# UART0_UART0 register map
Vendor: Texas Instruments
Peripheral module from a debugger description file (folder AM263).
Registers are 32-bit, access per field, reset 0x0 unless marked. A register's access mark holds for its fields unless they carry their own. Offsets are as the file gives them; lines under a group give offsets from that group; [hi:lo] are bit positions; {n}, {i} and the like mark numbered series; 'fields as' and 'values as' point back to an identical list; <NAME> marks a mode.

## UART0_UART0
0x00 UART0_DLL 8-bit rw
  [7:0] CLOCK_LSB — Used to store the 8-bit LSB divisor value
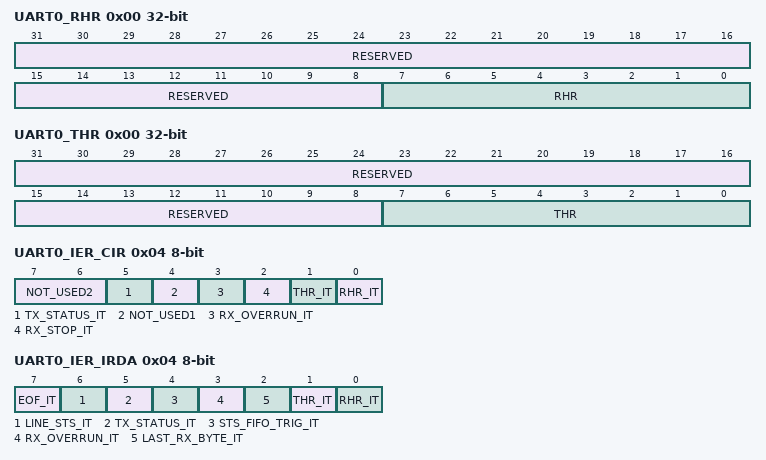
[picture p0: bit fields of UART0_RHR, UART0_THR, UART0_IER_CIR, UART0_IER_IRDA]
0x00 UART0_RHR ro
  [31:8] RESERVED — Not Defined
  [7:0] RHR — Receive holding register
0x00 UART0_THR
  [31:8] RESERVED ro — Not Defined
  [7:0] THR wo — TRANSMIT HOLDING REGISTER
0x04 UART0_DLH 8-bit rw
  [7:0] CLOCK_MSB — Used to store the 8-bit MSB divisor value
0x04 UART0_IER_CIR 8-bit rw
  [7:6] NOT_USED2 — Not Defined
  [5] TX_STATUS_IT — Not Defined 0 | TX_STATUS_IT_VALUE_0Disables the TX status interrupt. 1 | TX_STATUS_IT_VALUE_1Enables the TX status interrupt.
  [4] NOT_USED1 — Not Defined
  [3] RX_OVERRUN_IT — Not Defined 0 | RX_OVERRUN_IT_VALUE_0Disables the RX overrun interrupt. 1 | RX_OVERRUN_IT_VALUE_1Enables the RX overrun interrupt.
  [2] RX_STOP_IT — Not Defined 0 | RX_STOP_IT_VALUE_0Disables the receive stop interrupt. 1 | RX_STOP_IT_VALUE_1Enables the receive stop interrupt.
  [1] THR_IT — Not Defined 0 | THR_IT_VALUE_0Disables the THR interrupt. 1 | THR_IT_VALUE_1Enables the THR interrupt.
  [0] RHR_IT — Not Defined 0 | RHR_IT_VALUE_0Disables the RHR interrupt. 1 | RHR_IT_VALUE_1Enables the RHR interrupt.
0x04 UART0_IER_IRDA 8-bit rw
  [7] EOF_IT — Not Defined 0 | EOF_IT_VALUE_0Disables the received EOF interrupt. 1 | EOF_IT_VALUE_1Enables the received EOF interrupt.
  [6] LINE_STS_IT — Not Defined 0 | LINE_STS_IT_VALUE_0Disables the receiver line status interrupt. 1 | LINE_STS_IT_VALUE_1Enables the receiver line status interrupt.
  [5] TX_STATUS_IT — Not Defined 0 | TX_STATUS_IT_VALUE_0Disables the TX status interrupt. 1 | TX_STATUS_IT_VALUE_1Enables the TX status interrupt.
  [4] STS_FIFO_TRIG_IT — Not Defined 0 | STS_FIFO_TRIG_IT_VALUE_0Disables the status FIFO trigger level interrupt. 1 | STS_FIFO_TRIG_IT_VALUE_1Enables the status FIFO trigger level interrupt.
  [3] RX_OVERRUN_IT — Not Defined 0 | RX_OVERRUN_IT_VALUE_0Disables the RX overrun interrupt. 1 | RX_OVERRUN_IT_VALUE_1Enables the RX overrun interrupt.
  [2] LAST_RX_BYTE_IT — Not Defined 0 | LAST_RX_BYTE_IT_VALUE_0Disables the last byte of frame in RX FIFO interrupt. 1 | LAST_RX_BYTE_IT_VALUE_1Enables the last byte of frame in RX FIFO interrupt.
  [1] THR_IT — Not Defined 0 | THR_IT_VALUE_0Disables the THR interrupt. 1 | THR_IT_VALUE_1Enables the THR interrupt.
  [0] RHR_IT — Not Defined 0 | RHR_IT_VALUE_0Disables the RHR interrupt. 1 | RHR_IT_VALUE_1Enables the RHR interrupt.
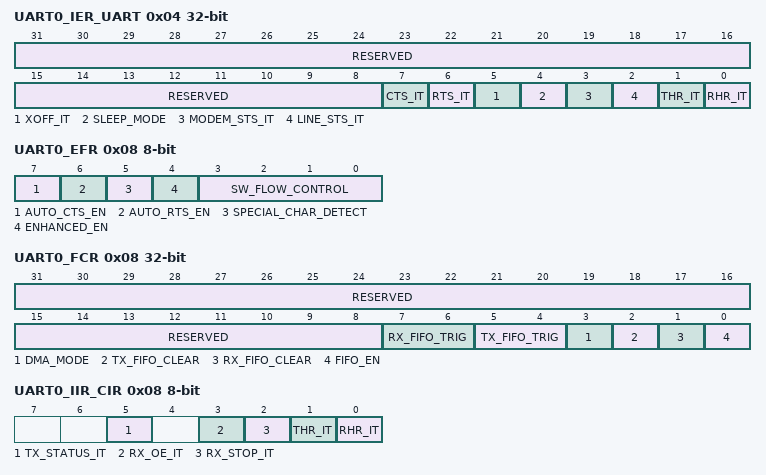
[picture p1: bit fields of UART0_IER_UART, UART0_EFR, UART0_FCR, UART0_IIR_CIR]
0x04 UART0_IER_UART
  [31:8] RESERVED ro — Not Defined
  [7] CTS_IT rw — Not Defined 0 | CTS_IT_VALUE_0Disables the CTS* interrupt 1 | CTS_IT_VALUE_1Enables the CTS* interrupt
  [6] RTS_IT rw — Not Defined 0 | RTS_IT_VALUE_0Disables the RTS* interrupt 1 | RTS_IT_VALUE_1Enables the RTS* interrupt
  [5] XOFF_IT rw — Not Defined 0 | XOFF_IT_VALUE_0Disables the XOFF interrupt 1 | XOFF_IT_VALUE_1Enables the XOFF interrupt
  [4] SLEEP_MODE rw — Not Defined 0 | SLEEP_MODE_VALUE_0Disables sleep mode 1 | SLEEP_MODE_VALUE_1Enables sleep mode (stop baud rate clock when the module is inactive)
  [3] MODEM_STS_IT rw — Not Defined 0 | MODEM_STS_IT_VALUE_0Disables the modem status register interrupt 1 | MODEM_STS_IT_VALUE_1Enables the modem status register interrupt
  [2] LINE_STS_IT rw — Not Defined 0 | LINE_STS_IT_U_VALUE_0Disables the receiver line status interrupt 1 | LINE_STS_IT_U_VALUE_1Enables the receiver line status interrupt
  [1] THR_IT rw — Not Defined 0 | THR_IT_VALUE_0Disables the THR interrupt 1 | THR_IT_VALUE_1Enables the THR interrupt
  [0] RHR_IT rw — Not Defined 0 | RHR_IT_VALUE_0Disables the RHR interrupt and time out interrupt. 1 | RHR_IT_VALUE_1Enables the RHR interrupt and time out interrupt.
0x08 UART0_EFR 8-bit rw
  [7] AUTO_CTS_EN — Auto-CTS enable bit. 0: Normal operation. 1: Auto-CTS flow control is enabled i.e. transmission is halted when the CTS* pin is high (inactive).
  [6] AUTO_RTS_EN — Auto-RTS enable bit. 0: Normal operation. 1: Auto- RTS flow control is enabled i.e. RTS* pin goes high (inactive) when the receiver FIFO HALT trigger level, TCR[3:0], is reached, and goes low (active) when the receiver FIFO RESTORE transmission trigger level is reached.
  [5] SPECIAL_CHAR_DETECT — 0: Normal operation. 1: Special character detect enable. Received data is compared with XOFF2 data. If a match occurs the received data is transferred to RX FIFO and IIR bit 4 is set to 1 to indicate a special character has been detected.
  [4] ENHANCED_EN — Enhanced functions write enable bit. 0: Disables writing to IER bits 4-7, FCR bits 4-5, and MCR bits 5-7. 1: Enables writing to IER bits 4-7, FCR bits 4-5, and MCR bits 5-7.
  [3:0] SW_FLOW_CONTROL — Combinations of Software flow control can be selected by programming bit 3 - bit 0. See Software Flow Control Options
0x08 UART0_FCR
  [31:8] RESERVED ro — Not Defined
  [7:6] RX_FIFO_TRIG wo — Sets the trigger level for the RX FIFO:If SCR[7] = 0 and TLR[7:4] = 0000:00: 8 characters01: 16 characters10: 56 characters11: 60 charactersIf SCR[7] = 0 and TLR[7:4] != 0000, RX_FIFO_TRIG is not considered.If SCR[7]=1, RX_FIFO_TRIG is 2 LSB of the trigger level [1-63 on 6 bits] with the granularity 1.
  [5:4] TX_FIFO_TRIG wo — Sets the trigger level for the TX FIFO:If SCR[6] = 0 and TLR[3:0] = 0000:00: 8 spaces01: 16 spaces10: 32 spaces11: 56 spacesIf SCR[6] = 0 and TLR[3:0] != 0000, TX_FIFO_TRIG is not considered.If SCR[6]=1, TX_FIFO_TRIG is 2 LSB of the trigger level [1-63 on 6 bits] with the granularity 1
  [3] DMA_MODE wo — This register is considered if SCR[0] = 0. Write0 | DMA_MODE_VALUE_0DMA_MODE 0 (No DMA) Write1 | DMA_MODE_VALUE_1DMA_MODE 1 (UART_nDMA_REQ[0] in TX, UART_nDMA_REQ[1] in RX)
  [2] TX_FIFO_CLEAR wo — Not Defined Write0 | TX_FIFO_CLEAR_VALUE_0No change Write1 | TX_FIFO_CLEAR_VALUE_1Clears the transmit FIFO and resets its counter logic to zero. Returns to zero after clearing FIFO.
  [1] RX_FIFO_CLEAR wo — Not Defined Write0 | RX_FIFO_CLEAR_VALUE_0No change Write1 | RX_FIFO_CLEAR_VALUE_1Clears the receive FIFO and resets its counter logic to zero. Returns to zero after clearing FIFO.
  [0] FIFO_EN wo — Not Defined Write0 | FIFO_EN_VALUE_0Disables the transmit and receive FIFOs. The transmit and receive holding registers are one byte FIFOs. Write1 | FIFO_EN_VALUE_1: Enables the transmit and receive FIFOs.The transmit and receive holding registers are 64-bytes FIFOs.
0x08 UART0_IIR_CIR 8-bit ro
  [5] TX_STATUS_IT — Not Defined Read0 | TX_STATUS_IT_VALUE_0TX status interrupt inactive Read1 | TX_STATUS_IT_VALUE_1TX status interrupt active
  [3] RX_OE_IT — Not Defined Read0 | RX_OE_IT_VALUE_0RX overrun interrupt inactive Read1 | RX_OE_IT_VALUE_1RX overrun interrupt active
  [2] RX_STOP_IT — Not Defined Read0 | RX_STOP_IT_VALUE_0Receive stop interrupt inactive Read1 | RX_STOP_IT_VALUE_1Receive stop interrupt active
  [1] THR_IT — Not Defined Read0 | THR_IT_VALUE_0THR interrupt inactive Read1 | THR_IT_VALUE_1THR interrupt active
  [0] RHR_IT — Not Defined Read0 | RHR_IT_VALUE_0RHR interrupt inactive Read1 | RHR_IT_VALUE_1RHR interrupt active
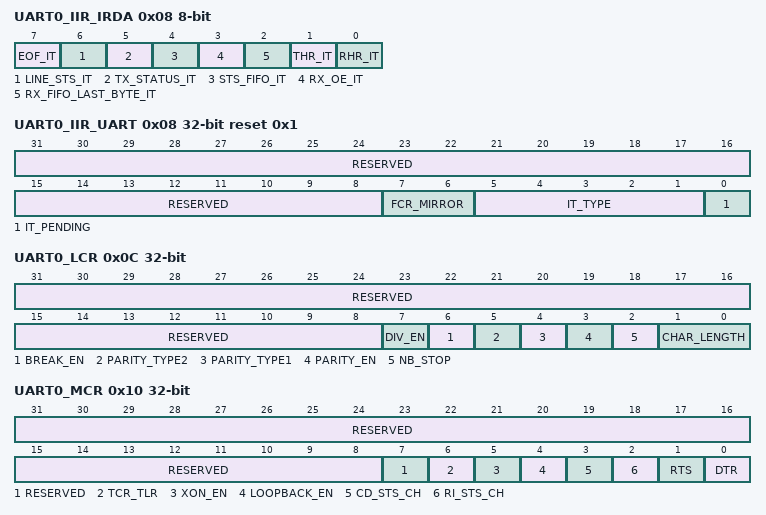
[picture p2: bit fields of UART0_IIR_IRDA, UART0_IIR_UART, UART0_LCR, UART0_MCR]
0x08 UART0_IIR_IRDA 8-bit ro
  [7] EOF_IT — Not Defined Read0 | EOF_IT_VALUE_0Received EOF interrupt inactive Read1 | EOF_IT_VALUE_1Received EOF interrupt active
  [6] LINE_STS_IT — Not Defined Read0 | LINE_STS_IT_VALUE_0Receiver line status interrupt inactive Read1 | LINE_STS_IT_VALUE_1Receiver line status interrupt active
  [5] TX_STATUS_IT — Not Defined Read0 | TX_STATUS_IT_VALUE_0TX status interrupt inactive Read1 | TX_STATUS_IT_VALUE_1TX status interrupt active
  [4] STS_FIFO_IT — Not Defined Read0 | STS_FIFO_IT_VALUE_0Status FIFO trigger level interrupt inactive Read1 | STS_FIFO_IT_VALUE_1Status FIFO trigger level interrupt active
  [3] RX_OE_IT — Not Defined Read0 | RX_OE_IT_VALUE_0RX overrun interrupt inactive Read1 | RX_OE_IT_VALUE_1RX overrun interrupt active
  [2] RX_FIFO_LAST_BYTE_IT — Not Defined Read0 | RX_FIFO_LAST_BYTE_IT_VALUE_0Last byte of frame in RX FIFO interrupt inactive Read1 | RX_FIFO_LAST_BYTE_IT_VALUE_1Last byte of frame in RX FIFO interrupt active
  [1] THR_IT — Not Defined Read0 | THR_IT_VALUE_0THR interrupt inactive Read1 | THR_IT_VALUE_1THR interrupt active
  [0] RHR_IT — Not Defined Read0 | RHR_IT_VALUE_0RHR interrupt inactive Read1 | RHR_IT_VALUE_1RHR interrupt active
0x08 UART0_IIR_UART ro reset 0x1
  [31:8] RESERVED — Not Defined
  [7:6] FCR_MIRROR — Mirror the contents of FCR[0] on both bits.
  [5:1] IT_TYPE — Not Defined Read0x00 | IT_TYPE_VALUE_0Modem Interrupt. Priority=4 Read0x01 | IT_TYPE_VALUE_1THR interrupt. Priority=3 Read0x02 | IT_TYPE_VALUE_2RHR interrupt. Priority=2 Read0x03 | IT_TYPE_VALUE_3Receiver line status error. Priority=3 Read0x06 | IT_TYPE_VALUE_6Rx timeout. Priority=2 Read0x08 | IT_TYPE_VALUE_8Xoff/Special character. Priority=5 Read0x10 | IT_TYPE_VALUE_10CTS, RTS, DSR change state from active (low) to inactive (high). Priority=6
  [0] IT_PENDING — Not Defined Read0 | IT_PENDING_VALUE_0An interrupt is pending Read1 | IT_PENDING_VALUE_1No interrupt is pending
0x0C UART0_LCR
  [31:8] RESERVED ro — Not Defined
  [7] DIV_EN rw — Not Defined 0 | DIV_EN_VALUE_0Normal operating condition 1 | DIV_EN_VALUE_1Divisor latch enable. Allows to access to DLL, DLH and other registers (refer to the registers mapping)
  [6] BREAK_EN rw — Break control bit. 0 | BREAK_EN_VALUE_0Normal operating condition. 1 | BREAK_EN_VALUE_1Forces the transmitter output to go low to alert the communication terminal
  [5] PARITY_TYPE2 rw — Selects the forced parity format [if LCR[3] = 1]. If LCR[5] = 1 and LCR[4] = 0, the parity bit is forced to 1 in the transmitted and received data. If LCR[5] = 1 and LCR[4] = 1, the parity bit is forced to 0 in the transmitted and received data.
  [4] PARITY_TYPE1 rw — Not Defined 0 | PARITY_TYPE1_VALUE_0Odd parity is generated (if LCR[3] = 1) 1 | PARITY_TYPE1_VALUE_1Even parity is generated (if LCR[3] = 1)
  [3] PARITY_EN rw — Not Defined 0 | PARITY_EN_VALUE_0No parity 1 | PARITY_EN_VALUE_1A parity bit is generated during transmission and the receiver checks for received parity.
  [2] NB_STOP rw — Specifies the number of stop bits: 0 | NB_STOP_VALUE_01 stop bits (word length = 5, 6, 7, 8) 1 | NB_STOP_VALUE_11.5 stop bits (word length = 5) in USART mode. 2 stop bits (word length = 6, 7, 8)
  [1:0] CHAR_LENGTH rw — Specifies the word length to be transmitted or received. 0x0 | CHAR_LENGTH_VALUE_05 bits 0x1 | CHAR_LENGTH_VALUE_16 bits 0x2 | CHAR_LENGTH_VALUE_27 bits 0x3 | CHAR_LENGTH_VALUE_38 bits
0x10 UART0_XON1_ADDR1 8-bit rw
  [7:0] XON_WORD1 — Used to store the 8-bit XON1 character in UART modes and ADDR1 address 1 for IrDA modes.
0x10 UART0_MCR
  [31:8] RESERVED ro — Not Defined
  [7] RESERVED ro — Not Defined
  [6] TCR_TLR rw — Not Defined 0 | TCR_TLR_VALUE_0No action 1 | TCR_TLR_VALUE_1Enables access to the TCR and TLR registers.
  [5] XON_EN rw — Not Defined 0 | XON_EN_VALUE_0Disable 'XON any' function 1 | XON_EN_VALUE_1Enable 'XON any' function
  [4] LOOPBACK_EN rw — Not Defined 0 | LOOPBACK_EN_VALUE_0Normal operating mode 1 | LOOPBACK_EN_VALUE_1Enable local loopback mode (internal). In this mode the MCR[3:0] signals are looped back into MSR[7:4]. The transmit output is looped back to the receive input internally
  [3] CD_STS_CH rw — Not Defined 0 | CD_STS_CH_VALUE_0In loopback forces DCD* input high and IRQ outputs to inactive state. 1 | CD_STS_CH_VALUE_1In loopback forces DCD* input low and IRQ outputs to inactive state.
  [2] RI_STS_CH rw — Not Defined 0 | RI_STS_CH_VALUE_0In loopback forces RI* input high. 1 | RI_STS_CH_VALUE_1In loopback forces RI* input low.
  [1] RTS rw — In loop back controls MSR[4].If auto-RTS is enabled the RTS* output is controlled by hardware flow control. 0 | RTS_VALUE_0Force RTS* output to inactive (high). 1 | RTS_VALUE_1Force RTS* output to active (low).
  [0] DTR rw — Not Defined 0 | DTR_VALUE_0Force DTR* output to inactive (high). 1 | DTR_VALUE_1Force DTR* output to active (low).
0x14 UART0_XON2_ADDR2 8-bit rw
  [7:0] XON_WORD2 — Used to store the 8-bit XON2 character in UART modes and ADDR2 address 2 for IrDA modes.
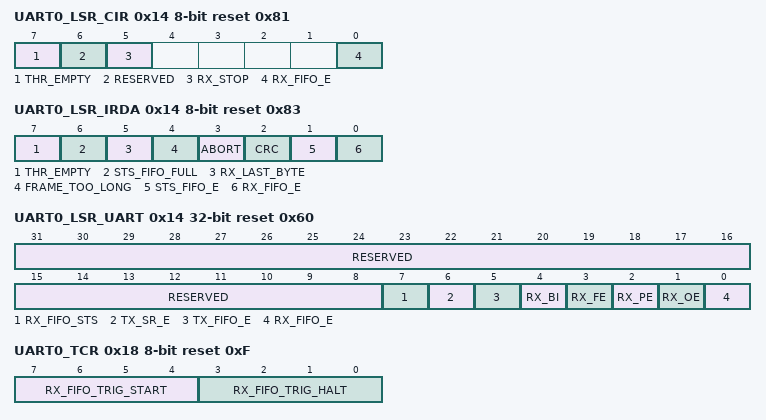
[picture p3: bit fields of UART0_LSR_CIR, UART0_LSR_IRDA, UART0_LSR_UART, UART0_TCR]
0x14 UART0_LSR_CIR 8-bit ro reset 0x81
  [7] THR_EMPTY — Not Defined Read0 | THR_EMPTY_VALUE_0Transmit holding register (TX FIFO) is not empty Read1 | THR_EMPTY_VALUE_1Transmit hold register (TX FIFO) is empty. The transmission is not necessarily completed
  [6] RESERVED — Not Defined
  [5] RX_STOP — The RX_STOP is generated based on the value set in the BOF Length register (EBLR). It is cleared on a single read of the LSR register Read0 | RX_STOP_VALUE_0Reception is on going or waiting for a new frame Read1 | RX_STOP_VALUE_1Reception is completed
  [0] RX_FIFO_E — Not Defined Read0 | RX_FIFO_E_VALUE_0No data in the receive FIFO Read1 | RX_FIFO_E_VALUE_1At least one data character in the RX FIFO
0x14 UART0_LSR_IRDA 8-bit ro reset 0x83
  [7] THR_EMPTY — Not Defined Read0 | THR_EMPTY_VALUE_0Transmit holding register (TX FIFO) is not empty Read1 | THR_EMPTY_VALUE_1Transmit hold register (TX FIFO) is empty. The transmission is not necessarily completed
  [6] STS_FIFO_FULL — Not Defined Read0 | STS_FIFO_FULL_VALUE_0Status FIFO not full Read1 | STS_FIFO_FULL_VALUE_1Status FIFO full
  [5] RX_LAST_BYTE — Not Defined Read0 | RX_LAST_BYTE_VALUE_0The RX FIFO (RHR) does not contain the last byte of the frame to be read Read1 | RX_LAST_BYTE_VALUE_1The RX FIFO (RHR) contains the last byte of the frame to be read.This bit is only set when the last byte of a frame is available to be read. It is used to determine the frame boundary. It is cleared on a single read of the LSR register
  [4] FRAME_TOO_LONG — Not Defined Read0 | FRAME_TOO_LONG_VALUE_0No frame-too-long error in frame Read1 | FRAME_TOO_LONG_VALUE_1Frame-too-long error in the frame at the top of the STATUS FIFO, [next character to be read]. This bit is set to 1 when a frame exceeding the maximum length (set by RXFLH and RXFLL registers) has been received. When this error is detected, current frame reception is terminated. Reception is stopped until the next START flag is detected
  [3] ABORT — Not Defined Read0 | ABORT_VALUE_0No abort pattern error in frame Read1 | ABORT_VALUE_1Abort pattern is received. SIR , MIR: Abort pattern. FIR: Illegal symbol
  [2] CRC — Not Defined Read0 | CRC_VALUE_0No CRC error in frame Read1 | CRC_VALUE_1CRC error in the frame at the top of the STATUS FIFO (next character to be read)
  [1] STS_FIFO_E — Not Defined Read0 | STS_FIFO_E_VALUE_0Status FIFO not empty Read1 | STS_FIFO_E_VALUE_1Status FIFO empty
  [0] RX_FIFO_E — Not Defined Read0 | RX_FIFO_E_VALUE_0No data in the receive FIFO Read1 | RX_FIFO_E_VALUE_1At least one data character in the RX FIFO
0x14 UART0_LSR_UART ro reset 0x60
  [31:8] RESERVED — Not Defined
  [7] RX_FIFO_STS — Not Defined Read0 | RX_FIFO_STS_VALUE_0Normal operation Read1 | RX_FIFO_STS_VALUE_1At least one parity error, framing error or break indication in the RX FIFO. Bit 7 is cleared when no more errors are present in the RX FIFO.
  [6] TX_SR_E — Not Defined Read0 | TX_SR_E_VALUE_0Transmitter hold (TX FIFO) and shift registers are not empty. Read1 | TX_SR_E_VALUE_1Transmitter hold (TX FIFO) and shift registers are empty
  [5] TX_FIFO_E — Not Defined Read0 | TX_FIFO_E_VALUE_0Transmit hold register (TX FIFO) is not empty Read1 | TX_FIFO_E_VALUE_1Transmit hold register (TX FIFO) is empty. The transmission is not necessarily completed.
  [4] RX_BI — Not Defined Read0 | RX_BI_VALUE_0No break condition Read1 | RX_BI_VALUE_1A break was detected while the data being read from the RX FIFO was being received. (i.e. RX input was low for one character + 1 bit time frame).
  [3] RX_FE — Not Defined Read0 | RX_FE_VALUE_0No framing error in data being read from RX FIFO. Read1 | RX_FE_VALUE_1Framing error occurred in data being read from RX FIFO.(received data did not have a valid stop bit)
  [2] RX_PE — Not Defined Read0 | RX_PE_VALUE_0No parity error in data being read from RX FIFO. Read1 | RX_PE_VALUE_1Parity error in data being read from RX FIFO
  [1] RX_OE — Not Defined Read0 | RX_OE_VALUE_0No overrun error Read1 | RX_OE_VALUE_1Overrun error has occurred. Set when the character held in the receive shift register is not transferred to the RX FIFO. This case can occurs only when receive FIFO is full.
  [0] RX_FIFO_E — Not Defined Read0 | RX_FIFO_E_VALUE_0No data in the receive FIFO Read1 | RX_FIFO_E_VALUE_1At least one data character in the RX FIFO
0x18 UART0_TCR 8-bit rw reset 0xF
  [7:4] RX_FIFO_TRIG_START — RX FIFO trigger level to RESTORE transmission (0 - 60)
  [3:0] RX_FIFO_TRIG_HALT — RX FIFO trigger level to HALT transmission (0 - 60)
0x18 UART0_XOFF1 8-bit rw
  [7:0] XOFF_WORD1 — Used to store the 8-bit XOFF1 character in used in UART modes.
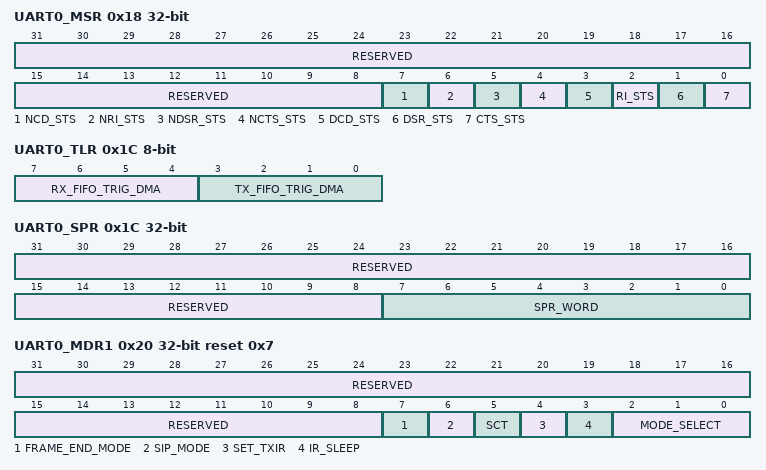
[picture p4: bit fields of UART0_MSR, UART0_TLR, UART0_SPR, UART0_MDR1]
0x18 UART0_MSR ro
  [31:8] RESERVED — Not Defined
  [7] NCD_STS — This bit is the complement of the DCD* input. In loop-back mode it is equivalent to MCR[3]
  [6] NRI_STS — This bit is the complement of the RI* input. In loop-back mode it is equivalent to MCR[2]
  [5] NDSR_STS — This bit is the complement of the DSR* input. In loop-back mode, it is equivalent to MCR[0]
  [4] NCTS_STS — This bit is the complement of the CTS* input. In loop-back mode it is equivalent to MCR[1]
  [3] DCD_STS — Indicates that DCD* input [or MCR[3] in loop back] has changed. Cleared on a read.
  [2] RI_STS — Indicates that RI* input [or MCR[2] in loop back] has changed state from low to high. Cleared on a read.
  [1] DSR_STS — Not Defined Read1 | DSR_STS_VALUE_1Indicates that DSR* input (or MCR[0] in loop back) has changed state. Cleared on a read
  [0] CTS_STS — Not Defined Read1 | CTS_STS_VALUE_1Indicates that CTS* input (or MCR[1] in loop back) has changed state. Cleared on a read.
0x1C UART0_TLR 8-bit rw
  [7:4] RX_FIFO_TRIG_DMA — Receive FIFO trigger level
  [3:0] TX_FIFO_TRIG_DMA — Transmit FIFO trigger level
0x1C UART0_XOFF2 8-bit rw
  [7:0] XOFF_WORD2 — Used to store the 8-bit XOFF2 character in used in UART modes.
0x1C UART0_SPR
  [31:8] RESERVED ro — Not Defined
  [7:0] SPR_WORD rw — Scratchpad register
0x20 UART0_MDR1 reset 0x7
  [31:8] RESERVED ro — Not Defined
  [7] FRAME_END_MODE rw — IrDA mode only. 0 | FRAME_END_MODE_VALUE_0Frame-length method 1 | FRAME_END_MODE_VALUE_1Set EOT bit method
  [6] SIP_MODE rw — MIR/FIR modes only. 0 | SIP_MODE_VALUE_0Manual SIP mode: SIP is generated with the control of ACREG[3] 1 | SIP_MODE_VALUE_1Automatic SIP mode: SIP is generated after each transmission.
  [5] SCT rw — Store and control the transmission 0 | SCT_VALUE_0Starts the Infrared transmission as soon as a value is written to THR 1 | SCT_VALUE_1Starts the Infrared transmission with the control of ACREG[2]. Note: before starting any transmission, there must be no reception on going.
  [4] SET_TXIR rw — Used to configure the infrared transceiver. 0 | SET_TXIR_VALUE_0No action if MDR2[7]=0. TXIR pin output is forced low if MDR2[7]=1 1 | SET_TXIR_VALUE_1TXIR pin output is forced high (not dependant of MDR2[7] value).
  [3] IR_SLEEP rw — Not Defined 0 | IR_SLEEP_VALUE_0IrDA/CIR sleep mode disabled 1 | IR_SLEEP_VALUE_1IrDA/CIR sleep mode enabled
  [2:0] MODE_SELECT rw — Not Defined 0x0 | MODE_SELECT_VALUE_0UART 16x mode 0x1 | MODE_SELECT_VALUE_1SIR mode 0x2 | MODE_SELECT_VALUE_2UART 16x auto-baud 0x3 | MODE_SELECT_VALUE_3UART 13x mode 0x4 | MODE_SELECT_VALUE_4MIR mode 0x5 | MODE_SELECT_VALUE_5FIR mode 0x6 | MODE_SELECT_VALUE_6CIR mode 0x7 | MODE_SELECT_VALUE_7Disable (default state)
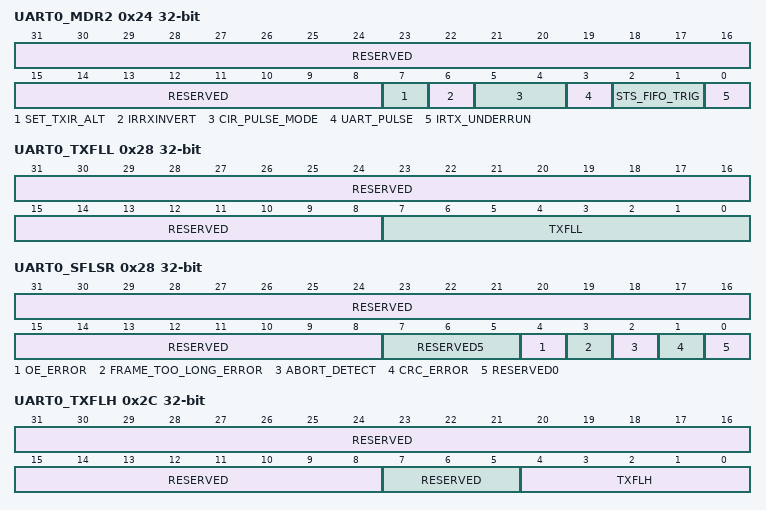
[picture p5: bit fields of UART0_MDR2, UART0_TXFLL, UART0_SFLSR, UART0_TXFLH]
0x24 UART0_MDR2
  [31:8] RESERVED ro — Not Defined
  [7] SET_TXIR_ALT rw — Provide alternate functionnality for MDR1[4] [SET_TXIR] 0 | SET_TXIR_ALT_VALUE_0Normal mode 1 | SET_TXIR_ALT_VALUE_1Alternate mode for SET_TXIR
  [6] IRRXINVERT rw — Only for IR mode [IRDA & CIR]Invert RX pin inside the module before the voting or sampling system logic of the infra red block. This will not affect the RX path in UART Modem modes. 0 | IRRXINVERT_VALUE_0inversion is performed 1 | IRRXINVERT_VALUE_1No inversion is performed
  [5:4] CIR_PULSE_MODE rw — CIR Pulse modulation definition. It defines high level of the pulse width associated with a digit: 0x0 | CIR_PULSE_MODE_VALUE_0Pulse width of 3 from 12 cycles 0x1 | CIR_PULSE_MODE_VALUE_1Pulse width of 4 from 12 cycles 0x2 | CIR_PULSE_MODE_VALUE_2Pulse width of 5 from 12 cycles 0x3 | CIR_PULSE_MODE_VALUE_3Pulse width of 6 from 12 cycles
  [3] UART_PULSE rw — UART mode only. Used to allow pulse shaping in UART mode. 0 | UART_PULSE_VALUE_0normal UART mode 1 | UART_PULSE_VALUE_1UART mode with a pulse shaping
  [2:1] STS_FIFO_TRIG rw — Only for IR-IRDA mode.Frame Status FIFO Threshold select: 0x0 | STS_FIFO_TRIG_VALUE_01 entry 0x1 | STS_FIFO_TRIG_VALUE_14 entries 0x2 | STS_FIFO_TRIG_VALUE_27 entries 0x3 | STS_FIFO_TRIG_VALUE_38 entries
  [0] IRTX_UNDERRUN ro — IRDA Transmission status interrupt.When the IIR[5] interrupt occurs, the meaning of the interrupt is : Read0 | IRTX_UNDERRUN_VALUE_0the last bit of the frame has been transmitted successfully without error. Read1 | IRTX_UNDERRUN_VALUE_1an underrun has occurred. The last bit of the frame has been transmitted but with an underrun error present. The bit is reset to '0' when the RESUME register is read.
0x28 UART0_TXFLL
  [31:8] RESERVED ro — Not Defined
  [7:0] TXFLL wo — LSB register used to specify the frame length
0x28 UART0_SFLSR ro
  [31:8] RESERVED — Not Defined
  [7:5] RESERVED5 — Not Defined
  [4] OE_ERROR — Not Defined Read1 | OE_ERROR_VALUE_1Overrun error in RX FIFO when frame at top of RX FIFO was received.
  [3] FRAME_TOO_LONG_ERROR — Not Defined Read1 | FRAME_TOO_LONG_ERROR_VALUE_1Frame-length too long error in frame at top of RX FIFO.
  [2] ABORT_DETECT — Not Defined Read1 | ABORT_DETECT_VALUE_1Abort pattern detected in frame at top of RX FIFO
  [1] CRC_ERROR — Not Defined Read1 | CRC_ERROR_VALUE_1CRC error in frame at top of RX FIFO. top of RX FIFO = Next frame to be read from RX FIFO
  [0] RESERVED0 — Not Defined
0x2C UART0_TXFLH
  [31:8] RESERVED ro — Not Defined
  [7:5] RESERVED ro — Not Defined
  [4:0] TXFLH wo — MSB register used to specify the frame length
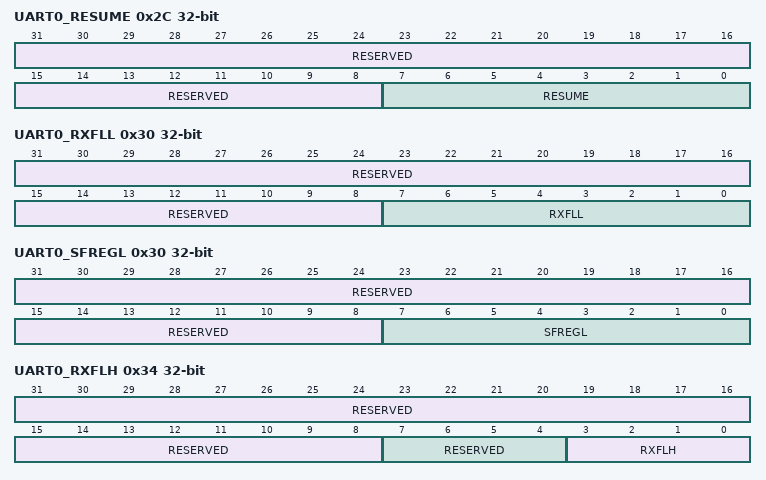
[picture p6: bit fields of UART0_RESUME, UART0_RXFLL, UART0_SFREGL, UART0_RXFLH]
0x2C UART0_RESUME ro
  [31:8] RESERVED — Not Defined
  [7:0] RESUME — Dummy read to restart the TX or RX
0x30 UART0_RXFLL
  [31:8] RESERVED ro — Not Defined
  [7:0] RXFLL wo — LSB register used to specify the frame length in reception
0x30 UART0_SFREGL ro
  [31:8] RESERVED — Not Defined
  [7:0] SFREGL — LSB part of the frame length
0x34 UART0_RXFLH
  [31:8] RESERVED ro — Not Defined
  [7:4] RESERVED ro — Not Defined
  [3:0] RXFLH wo — MSB register used to specify the frame length in reception
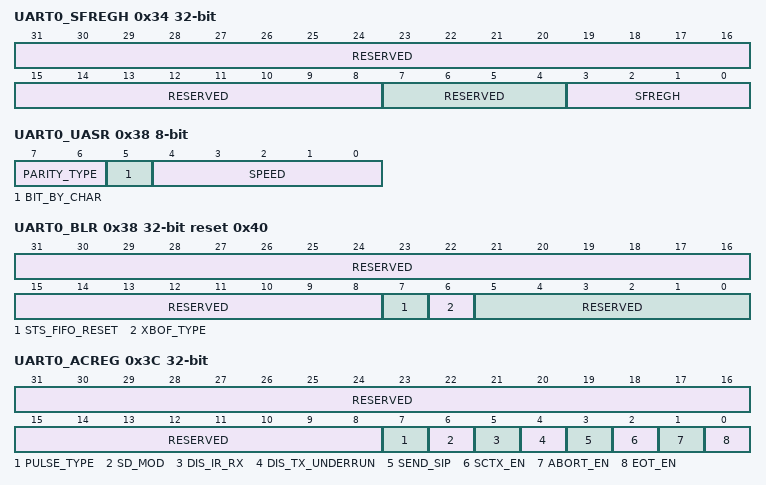
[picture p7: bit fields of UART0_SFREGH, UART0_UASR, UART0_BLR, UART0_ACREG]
0x34 UART0_SFREGH ro
  [31:8] RESERVED — Not Defined
  [7:4] RESERVED — Not Defined
  [3:0] SFREGH — MSB part of the frame length
0x38 UART0_UASR 8-bit ro
  [7:6] PARITY_TYPE — 00 => No Parity identified. 01 => Parity space. 10 => Even Parity. 11 => Odd Parity
  [5] BIT_BY_CHAR — 0 => 7 bits character identified. 1 => 8 bits character identified
  [4:0] SPEED — Used to report the speed identified. 00000 => No speed identified. 00001 => 115200 bauds. 00010 => 57600 bauds. 00011 => 38400 bauds. 00100 => 28800 bauds. 00101 => 19200 bauds. 00110 => 14400 bauds. 00111 => 9600 bauds. 01000 => 4800 bauds. 01001 => 2400 bauds. 01010 => 1200 bauds
0x38 UART0_BLR reset 0x40
  [31:8] RESERVED ro — Not Defined
  [7] STS_FIFO_RESET rw — Status FIFO reset. This bit is self-clearing
  [6] XBOF_TYPE rw — SIR xBOF select. 0 | XBOF_TYPE_VALUE_00xFF 1 | XBOF_TYPE_VALUE_10xC0
  [5:0] RESERVED ro — Not Defined
0x3C UART0_ACREG
  [31:8] RESERVED ro — Not Defined
  [7] PULSE_TYPE rw — SIR pulse width select: 0 | PULSE_TYPE_VALUE_03/16 of baud-rate pulse width 1 | PULSE_TYPE_VALUE_11.6us
  [6] SD_MOD rw — Primary output used to configure transceivers. Connected to the SD/MODE input pin of IrDA transceivers. 0 | SD_MOD_VALUE_0SD pin is set to high 1 | SD_MOD_VALUE_1SD pin is set to low
  [5] DIS_IR_RX rw — Not Defined 0 | DIS_IR_RX_VALUE_0Normal operation (RX input automatically disabled during transmit but enabled outside of transmit operation). 1 | DIS_IR_RX_VALUE_1Disables RX input (permanent state - independent of transmit).
  [4] DIS_TX_UNDERRUN rw — It is recommended to disable TX FIFO underrun capability by masking corresponding underrun interrupt. When disabling underrun by setting ACREG[4]=1, garbage data is sent over TX line. 0 | DIS_TX_UNDERRUN_VALUE_0Long stop bits cannot be transmitted, TX underrun is enabled 1 | DIS_TX_UNDERRUN_VALUE_1Long stop bits can be transmitted, TX underrun is disabled
  [3] SEND_SIP rw — MIR/FIR Modes only.Send Serial Infrared Interaction Pulse [SIP]If this bit is set during a MIR/FIR transmission, the SIP will be send at the end of it.This bit automatically gets cleared at the end of the SIP transmission. 0 | SEND_SIP_VALUE_0No action 1 | SEND_SIP_VALUE_1Send SIP pulse.
  [2] SCTX_EN rw — Store and controlled TX start. When MDR1[5] = 1 and the LH writes 1 to this bit the TX state machine starts frame transmission. This bit is self-clearing.
  [1] ABORT_EN rw — Frame Abort. The LH can intentionally abort transmission of a frame by writing 1 to this bit. Neither the end flag nor the CRC bits are appended to the frame. If transmit FIFO is not empty and MDR1[5]=1, UART IrDA will start a new transfer with data of previous frame as soon as abort frame has been sent. Therefore, TX FIFO must be reset before sending an abort frame.
  [0] EOT_EN rw — EOT [end of transmission] bit. The LH writes 1 to this bit just before it writes the last byte to the TX FIFO in set-EOT bit frame closing method. This bit automatically gets cleared when the LH writes to the THR [TX FIFO].
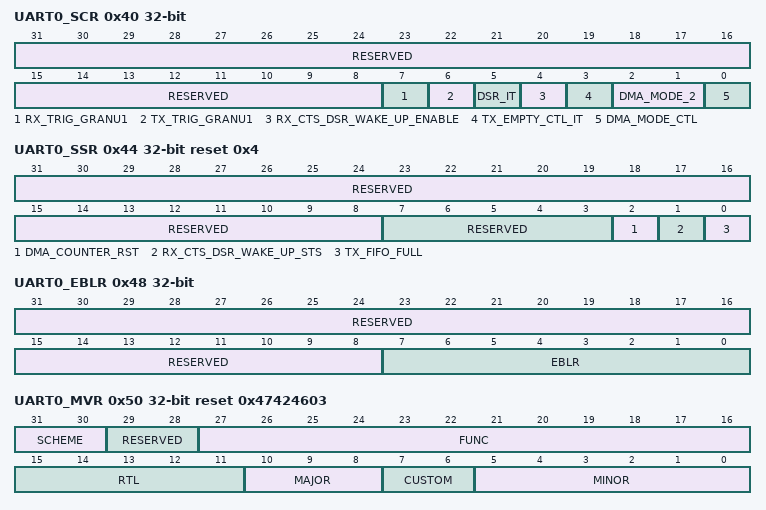
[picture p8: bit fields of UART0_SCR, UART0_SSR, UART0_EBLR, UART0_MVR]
0x40 UART0_SCR
  [31:8] RESERVED ro — Not Defined
  [7] RX_TRIG_GRANU1 rw — Not Defined 0 | RX_TRIG_GRANU1_VALUE_0DISABLES THE GRANULARITY OF 1 FOR TRIGGER RX LEVEL. 1 | RX_TRIG_GRANU1_VALUE_1ENABLES THE GRANULARITY OF 1 FOR TRIGGER RX LEVEL.
  [6] TX_TRIG_GRANU1 rw — Not Defined 0 | TX_TRIG_GRANU1_VALUE_0DISABLES THE GRANULARITY OF 1 FOR TRIGGER TX LEVEL. 1 | TX_TRIG_GRANU1_VALUE_1Enables the granularity of 1 for trigger TX level.
  [5] DSR_IT rw — Not Defined 0 | DSR_IT_VALUE_0DISABLES DSR* INTERRUPT. 1 | DSR_IT_VALUE_1ENABLES DSR* INTERRUPT.
  [4] RX_CTS_DSR_WAKE_UP_ENABLE rw — Not Defined 0 | RX_CTS_DSR_WAKE_UP_ENABLE_VALUE_0DISABLES THE WAKE UP INTERRUPT AND CLEARS SSR[1]. 1 | RX_CTS_DSR_WAKE_UP_ENABLE_VALUE_1Waits for a falling edge of pins RX, CTS* or DSR* to generate an interrupt
  [3] TX_EMPTY_CTL_IT rw — Not Defined 0 | TX_EMPTY_CTL_IT_VALUE_0Normal mode for THR interrupt (See UART mode interrupts table). 1 | TX_EMPTY_CTL_IT_VALUE_1THE THR INTERRUPT IS GENERATED WHEN TX FIFO AND TX SHIFT REGISTER ARE EMPTY.
  [2:1] DMA_MODE_2 rw — Used to specify the DMA mode valid if SCR[0] = 1 0x0 | DMA_MODE_2_VALUE_0DMA mode 0 (no DMA) 0x1 | DMA_MODE_2_VALUE_1DMA mode 1 (UART_nDMA_REQ[0] in TX, UART_nDMA_REQ[1] in RX) 0x2 | DMA_MODE_2_VALUE_2DMA mode 2 (UART_nDMA_REQ[0] in RX) 0x3 | DMA_MODE_2_VALUE_3DMA mode 3 (UART_nDMA_REQ[0] in TX)
  [0] DMA_MODE_CTL rw — Not Defined 0 | DMA_MODE_CTL_VALUE_0The DMA_MODE is set with FCR[3] 1 | DMA_MODE_CTL_VALUE_1The DMA_MODE is set with SCR[2:1]
0x44 UART0_SSR reset 0x4
  [31:8] RESERVED ro — Not Defined
  [7:3] RESERVED ro — Not Defined
  [2] DMA_COUNTER_RST rw — Not Defined 0 | DMA_COUNTER_RST_VALUE_0The DMA counter will not be reset if the corresponding FIFO is reset (via FCR[1] or FCR[2]) 1 | DMA_COUNTER_RST_VALUE_1The DMA counter will be reset if corresponding FIFO is reset (via FCR[1] or FCR[2])
  [1] RX_CTS_DSR_WAKE_UP_STS ro — Not Defined Read0 | RX_CTS_DSR_WAKE_UP_STS_VALUE_0No falling edge event on RX, CTS* and DSR* Read1 | RX_CTS_DSR_WAKE_UP_STS_VALUE_1A falling edge occurred on RX, CTS* or DSR*
  [0] TX_FIFO_FULL ro — Not Defined Read0 | TX_FIFO_FULL_VALUE_0TX FIFO is not full Read1 | TX_FIFO_FULL_VALUE_1TX FIFO is full.
0x48 UART0_EBLR
  [31:8] RESERVED ro — Not Defined
  [7:0] EBLR rw — IR-IRDA mode: This register allows to define up to 176 xBOFs, the maximum required by IrDA specification.IR-CIR mode: This register specifies the number of consecutive zeros to be received before generating the RX_STOP interrupt [IIR[2]].0x00: feature disabled.0x01: generate RX_STOP interrupt after receiving one zero bit....0xFF: generate RX_STOP interrupt after receiving 255 zero bits.
0x50 UART0_MVR ro reset 0x47424603
  [31:30] SCHEME — Scheme revision number of module
  [29:28] RESERVED — Not Defined
  [27:16] FUNC — Function revision number of module
  [15:11] RTL — Rtl revision number of module
  [10:8] MAJOR — Major revision number of the module.
  [7:6] CUSTOM — Custom revision number of the module.
  [5:0] MINOR — Minor revision number of the module.
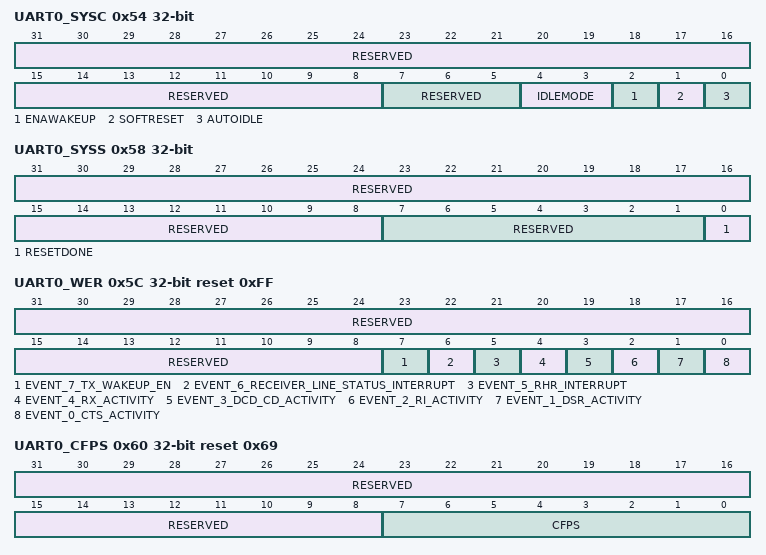
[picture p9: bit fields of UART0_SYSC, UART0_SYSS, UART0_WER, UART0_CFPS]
0x54 UART0_SYSC
  [31:8] RESERVED ro — Not Defined
  [7:5] RESERVED ro — Not Defined
  [4:3] IDLEMODE rw — POWER MANAGEMENT REQ/ACK CONTROLREF: OCP DESIGN GUIDELINES VERSION 1.1 0x0 | IDLEMODE_VALUE_0Force idle. An idle request is acknowledged unconditionally 0x1 | IDLEMODE_VALUE_1No-idle. An idle request is never acknowledged. 0x2 | IDLEMODE_VALUE_2Smart idle. Acknowledgement to an idle request is given based in the internal activity of the module. 0x3 | IDLEMODE_VALUE_3reserved
  [2] ENAWAKEUP rw — WAKE UP FEATURE CONTROL 0 | ENAWAKEUP_VALUE_0Wake up is disabled 1 | ENAWAKEUP_VALUE_1Wake up capability is enabled
  [1] SOFTRESET wo — Software reset. Set this bit to 1 to trigger a module reset. This bit is automatically reset by the hardware. During reads it always returns a 0. Write0 | SOFTRESET_VALUE_0Normal mode Write1 | SOFTRESET_VALUE_1The module is reset
  [0] AUTOIDLE rw — Internal OCP clock gating strategy 0 | AUTOIDLE_VALUE_0Clock is running 1 | AUTOIDLE_VALUE_1Automatic OCP clock gating strategy is applied, based on the OCP interface activity
0x58 UART0_SYSS ro
  [31:8] RESERVED — Not Defined
  [7:1] RESERVED — Not Defined
  [0] RESETDONE — Internal Reset Monitoring Read0 | RESETDONE_VALUE_0Internal Module Reset is ongoing Read1 | RESETDONE_VALUE_1Reset completed
0x5C UART0_WER reset 0xFF
  [31:8] RESERVED ro — Not Defined
  [7] EVENT_7_TX_WAKEUP_EN rw — Not Defined 0 | EVENT_7_TX_WAKEUP_EN_VALUE_0Event is not allowed to wake up the system 1 | EVENT_7_TX_WAKEUP_EN_VALUE_1EVENT CAN WAKE UP THE SYSTEM: Event can be: THR_IT or TX_DMA request and/or TX_SATUS_IT
  [6] EVENT_6_RECEIVER_LINE_STATUS_INTERRUPT rw — Not Defined 0 | EVENT_6_RECEIVER_LINE_STATUS_INTERRUPT_VALUE_0Event is not allowed to wake up the system 1 | EVENT_6_RECEIVER_LINE_STATUS_INTERRUPT_VALUE_1Event can wake up the system
  [5] EVENT_5_RHR_INTERRUPT rw — Not Defined 0 | EVENT_5_RHR_INTERRUPT_VALUE_0Event is not allowed to wake up the system 1 | EVENT_5_RHR_INTERRUPT_VALUE_1Event can wake up the system
  [4] EVENT_4_RX_ACTIVITY rw — Not Defined 0 | EVENT_4_RX_ACTIVITY_VALUE_0Event is not allowed to wake up the system 1 | EVENT_4_RX_ACTIVITY_VALUE_1Event can wake up the system
  [3] EVENT_3_DCD_CD_ACTIVITY rw — Not Defined 0 | EVENT_3_DCD_CD_ACTIVITY_VALUE_0Event is not allowed to wake up the system 1 | EVENT_3_DCD_CD_ACTIVITY_VALUE_1Event can wake up the system
  [2] EVENT_2_RI_ACTIVITY rw — Not Defined 0 | EVENT_2_RI_ACTIVITY_VALUE_0Event is not allowed to wake up the system 1 | EVENT_2_RI_ACTIVITY_VALUE_1Event can wake up the system
  [1] EVENT_1_DSR_ACTIVITY rw — Not Defined 0 | EVENT_1_DSR_ACTIVITY_VALUE_0Event is not allowed to wake up the system 1 | EVENT_1_DSR_ACTIVITY_VALUE_1Event can wake up the system
  [0] EVENT_0_CTS_ACTIVITY rw — Not Defined 0 | EVENT_0_CTS_ACTIVITY_VALUE_0Event is not allowed to wake up the system 1 | EVENT_0_CTS_ACTIVITY_VALUE_1Event can wake up the system
0x60 UART0_CFPS reset 0x69
  [31:8] RESERVED ro — Not Defined
  [7:0] CFPS rw — System clock frequency prescaler at [12x multiple]. Examples for CFPS values are given in the table below.Target Freq [KHz] CFPS [decimal] Actual Freq[KHz] 30 133 30.08 32.75 122 32.79 36 111 36.04 36.7 109 36.69 38* 105 38.1 40 100 40 56.8 70 57.14* configured at reset to this valueNote: CFPS = 0 is not supported.
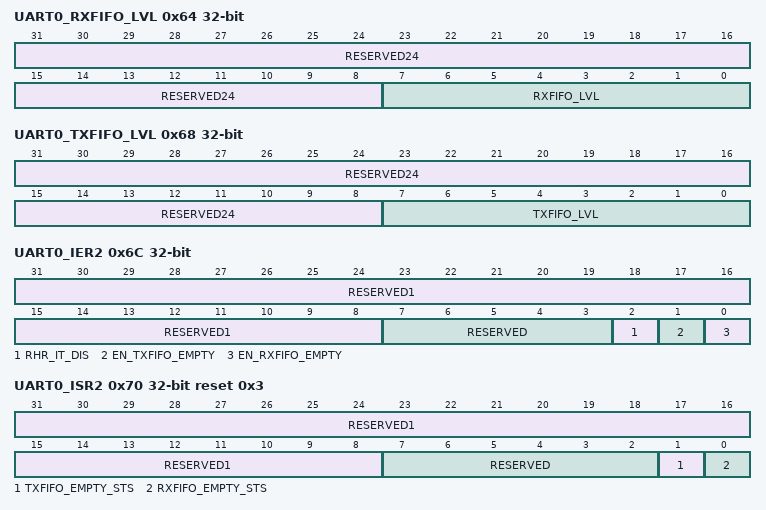
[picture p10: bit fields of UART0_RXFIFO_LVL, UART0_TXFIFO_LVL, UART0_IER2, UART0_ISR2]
0x64 UART0_RXFIFO_LVL ro
  [31:8] RESERVED24 — Not Defined
  [7:0] RXFIFO_LVL — Not Defined
0x68 UART0_TXFIFO_LVL ro
  [31:8] RESERVED24 — Not Defined
  [7:0] TXFIFO_LVL — Not Defined
0x6C UART0_IER2
  [31:8] RESERVED1 ro — Not Defined
  [7:3] RESERVED ro — Not Defined
  [2] RHR_IT_DIS rw — Not Defined 0 | RHR_IT_DIS_VALUE_0Enables the RHR interrupt. 1 | RHR_IT_DIS_VALUE_1Disables the RHR interrupt.
  [1] EN_TXFIFO_EMPTY rw — Enables[1]/DISABLES[00 EN_TXFIFO_EMPTY interrupt.
  [0] EN_RXFIFO_EMPTY rw — Enables[1]/disables[0] EN_RXFIFO_EMPTY interrupt.
0x70 UART0_ISR2 reset 0x3
  [31:8] RESERVED1 ro — Not Defined
  [7:2] RESERVED ro — Not Defined
  [1] TXFIFO_EMPTY_STS rw — TXFIFO interrupt pending 0 | TXFIFO_EMPTY_STS_VALUE_0TXFIFO_EMPTY interrupt not pending. 1 | TXFIFO_EMPTY_STS_VALUE_1TXFIFO_EMPTY interrupt pending.
  [0] RXFIFO_EMPTY_STS rw — RXFIFO interrupt pending 0 | RXFIFO_EMPTY_STS_VALUE_0RXFIFO_EMPTY interrupt not pending. 1 | RXFIFO_EMPTY_STS_VALUE_1RXFIFO_EMPTY interrupt pending.
0x74 UART0_FREQ_SEL rw reset 0x1A
  [7:0] FREQ_SEL — Sets the sample per bit if non default frequency is used. MDR3[1] must be set to 1 after this value is set. Must be equal or higher then 6.
0x78 UART0_ABAUD_1ST_CHAR ro
  [31:0] RESERVED — Not Defined
0x7C UART0_BAUD_2ND_CHAR ro
  [31:0] RESERVED — Not Defined
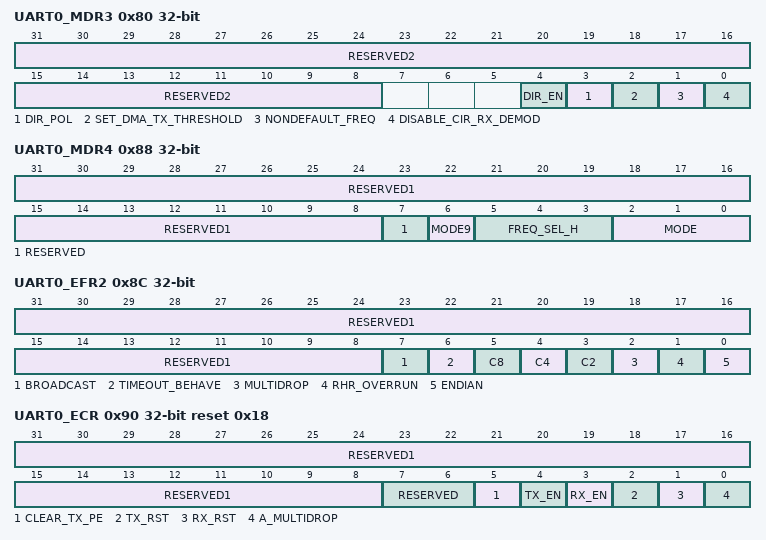
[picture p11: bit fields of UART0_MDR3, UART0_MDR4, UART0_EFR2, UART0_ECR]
0x80 UART0_MDR3
  [31:8] RESERVED2 ro — Not Defined
  [4] DIR_EN rw — RS-485 External Transceiver Direction Enable
  [3] DIR_POL rw — RS-485 External Transceiver Direction Polarity. 0 => TX: RTS=0, RX: RTS=1. 1 => TX: RTS=1, RX: RTS=0
  [2] SET_DMA_TX_THRESHOLD rw — Enable to set different TX DMA threshold then 64-trigger [usage of new register TX_DNA_THRESHOLD]
  [1] NONDEFAULT_FREQ rw — Enables[1]/Disables[0] using NONDEFAULT fclk frequencies
  [0] DISABLE_CIR_RX_DEMOD rw — Disables[1]/Enables[0] CIR RX demodulation 0 | DISABLE_CIR_RX_DEMOD_VALUE_0Enables CIR RX demodulation 1 | DISABLE_CIR_RX_DEMOD_VALUE_1Disables CIR RX demodulation
0x84 UART0_TX_DMA_THRESHOLD rw
  [5:0] TX_DMA_THRESHOLD — Use to manually set the TX DMA threshold level.
0x88 UART0_MDR4
  [31:8] RESERVED1 ro — Not Defined
  [7] RESERVED ro — Not Defined
  [6] MODE9 rw — 9-bit character length. When '1', overrides character length setting in LCR
  [5:3] FREQ_SEL_H rw — Upper 3 bits of FREQ_SEL register for higher division values, as required for example for FI/Di in ISO7816 mode
  [2:0] MODE rw — New modes [when set, overrides MDR1 modes] 0x0 | DISABLEDdisabled (no override) 0x1 | RESERVEDreserved 0x2 | SYNCH_EXTSynchronous mode with external clock 0x3 | SYNCH_GENSynchronous mode with generated clock 0x4 | ISO7816_0ISO 7816 mode T=0 0x5 | ISO7816_1ISO 7816 mode T=1 0x6 | RESERVED1reserved 0x7 | RESERVED2reserved
0x8C UART0_EFR2
  [31:8] RESERVED1 ro — Not Defined
  [7] BROADCAST rw — Enables broadcast address matching in multi-drop address match mode
  [6] TIMEOUT_BEHAVE rw — Specifies how timeout is measured 0 | _0timeout after at least one character has been received 1 | _1periodic timeout even when no character has been received
  [5] C8 rw — Value for ISO 7816 C8 pin for software control
  [4] C4 rw — Value for ISO 7816 C4 pin for software control
  [3] C2 rw — Value for ISO 7816 reset pin [software controllable]
  [2] MULTIDROP rw — Enables parity Multi-drop mode [overrides LCR[5..3]] when '1'
  [1] RHR_OVERRUN rw — RHR Overrun behaviour when buffer full 0 | DEFAULTdata in RHR is not overwritten (standard) 1 | ATMELdata in RHR is overwritten when buffer full (and FIFO disabled)
  [0] ENDIAN rw — Endianness 0 | LOW_ENDIANLittle Endian (LSB First) 1 | BIG_ENDIANBig Endian (MSB First)
0x90 UART0_ECR reset 0x18
  [31:8] RESERVED1 ro — Not Defined
  [7:6] RESERVED ro — Not Defined
  [5] CLEAR_TX_PE wo — Write 1 to clear parity error from the Transmitter to allow it to continue to try sending data [ISO7816 transmit only]
  [4] TX_EN rw — Enables/Disables the transmitter 0 | DISABLEDTransmitter is shut down 1 | ENABLEDTransmitter is working
  [3] RX_EN rw — Enables/Disables the receiver 0 | DISABLEDReceiver is shut down 1 | ENABLEDReceiver is operating
  [2] TX_RST wo — Writing '1' resets the transmitter
  [1] RX_RST wo — Writing '1' resets the receiver
  [0] A_MULTIDROP wo — In multi-drop mode, when written with the value '1' causes the next byte written into THR to be transmitted with the parity bit set, signaling an address
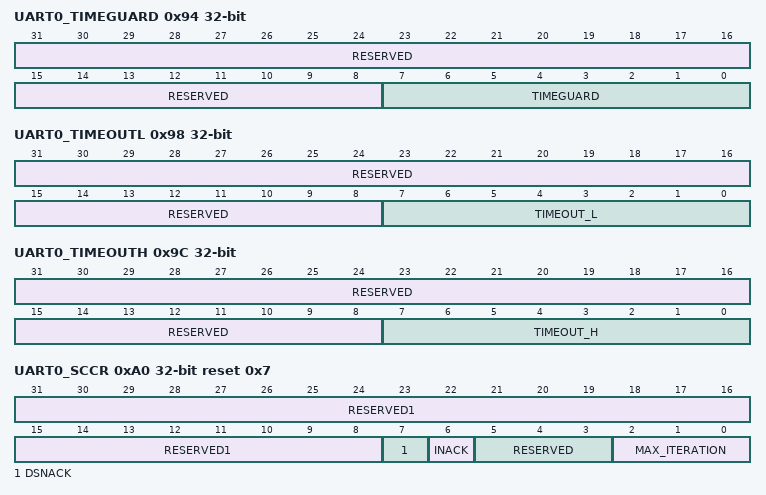
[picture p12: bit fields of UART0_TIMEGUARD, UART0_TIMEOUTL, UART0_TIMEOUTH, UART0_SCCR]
0x94 UART0_TIMEGUARD
  [31:8] RESERVED ro — Not Defined
  [7:0] TIMEGUARD rw — Specifies the amount of idle baud clocks [transmitter bit period] to insert between transmitted bytes, useful when comunicating with slower devices
0x98 UART0_TIMEOUTL
  [31:8] RESERVED ro — Not Defined
  [7:0] TIMEOUT_L rw — Custom timeout period in baud clocks, to override the internal value, when different from 0. [Lower byte of the 16 bit value]
0x9C UART0_TIMEOUTH
  [31:8] RESERVED ro — Not Defined
  [7:0] TIMEOUT_H rw — Custom timeout period in baud clocks, to override the internal value, when different from 0. [Higher byte of the 16 bit value]
0xA0 UART0_SCCR reset 0x7
  [31:8] RESERVED1 ro — Not Defined
  [7] DSNACK rw — Applies Max_Iteration to receiver aswell - when maximum number of NACKs have been returned, the receiver will accept the data regardless of error. The data will be loaded into the receiver FIFO and PE will be set when reading it.
  [6] INACK rw — Inhibit NACK when receiving, even if an error is received. The data will be loaded into the receiver FIFO and PE will be set when reading it.
  [5:3] RESERVED ro — Not Defined
  [2:0] MAX_ITERATION rw — Number of times to repeat transmitted character, if the receiver did not acknowledge. If not acknowledged after the max value is reached, the USART transmitter will set parity error, stop and not continue until it is cleared.
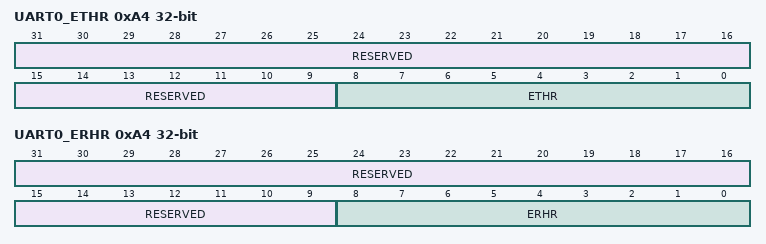
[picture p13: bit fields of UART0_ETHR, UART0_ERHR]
0xA4 UART0_ETHR
  [31:9] RESERVED ro — Not Defined
  [8:0] ETHR wo — Extended Transmit Holding Register - allows writing the full 9bit RHR
0xA4 UART0_ERHR ro
  [31:9] RESERVED — Not Defined
  [8:0] ERHR — Extended Receive Holding Register - allows accessing the full 9bit RHR
0xA8 UART0_MAR 8-bit rw
  [7:0] ADDRESS — Multidrop match address value
0xAC UART0_MMR 8-bit rw
  [7:0] MASK — Address match masking value ? writing a 0 to a bit means that the corresponding address bit will be ignored in matching
0xB0 UART0_MBR 8-bit rw
  [7:0] BROADCAST_ADDRESS — Broadcast address for address matching
